# psoc4axx register map
Vendor: Cypress Semiconductor; Series: PSoC4Axx; File version: 1.0
CPU: CM0PLUS r0p1, little endian, no MPU, no FPU, VTOR, 2 interrupt priority bits
Registers are 32-bit, read-write, reset 0x0 unless marked. A register's access mark holds for its fields unless they carry their own. Offsets are from the block's base; [hi:lo] are bit positions; {n}, {i} and the like mark numbered series; 'fields as' and 'values as' point back to an identical list.

## CTB0 — Continuous Time Block
Base 0x40300000
Same registers: CTB1 0x40310000
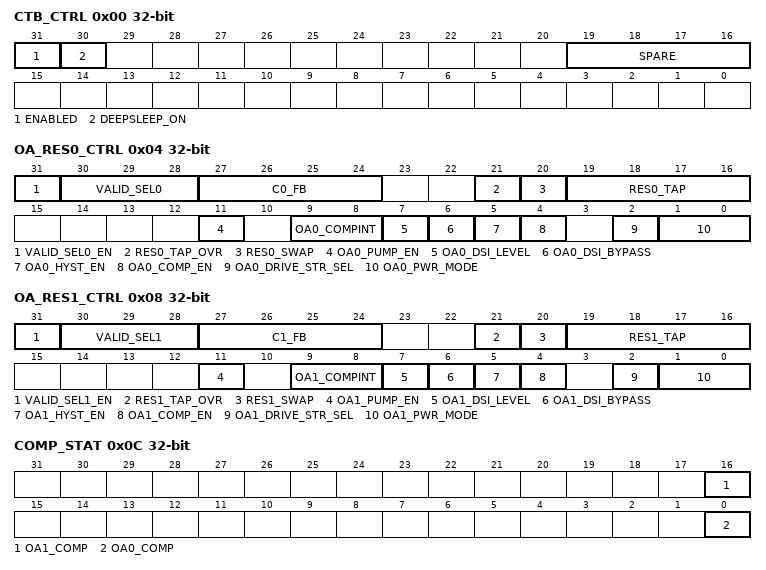
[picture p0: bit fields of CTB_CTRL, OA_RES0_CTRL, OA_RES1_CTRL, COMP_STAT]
0x00 CTB_CTRL — global CTB and power control
  [31] ENABLED — - 0: CTB IP disabled (put analog in power down, open all switches) - 1: CTB IP enabled
  [30] DEEPSLEEP_ON — - 0: CTB IP disabled off during DeepSleep power mode - 1: CTB IP remains enabled during DeepSleep power mode (if ENABLED=1)
  [19:16] SPARE — Spare controls, not yet designated, for late changes done with an ECO
0x04 OA_RES0_CTRL — Opamp0 and resistor0 control
  [31] VALID_SEL0_EN — Enable UAB Valid selection (UAB mode), otherwise ignore UAB Valid. Note that enabling UAB Valid selection also disables DeepSleep comparator operation.
  [30:28] VALID_SEL0 — Select which UAB Valid to use to sample the comparator output. This should match the UAB analog output connected to this comparator. The comparator output gets sampled at the negative edge of the selected UAB Valid signal. 0=UAB0 half 0 Valid output 1=UAB0 half 1 Valid output 2=UAB1 half 0 Valid output 3=UAB1 half 1 Valid output 4=UAB2 half 0 Valid output 5=UAB2 half 1 Valid output 6=UAB3 half 0 Valid output 7=UAB3 half 1 Valid output
  [27:24] C0_FB — Feed back Cap value
  [21] RES0_TAP_OVR — 1 - Override the control from hardware and close the switch connecting the resistor ladder tap point to the bottom of the ladder
  [20] RES0_SWAP — Swap Top and Bottom resistor value
  [19:16] RES0_TAP — PGA gain (resistor tap point): 0= gain 1.0 (disconnect resistor) 1= gain 1.42 2= gain 2.0 3= gain 2.78 4= gain 4.0 5= gain 5.82 6= gain 8.0 7= gain 10.67 8= gain 16.0 9= gain 21.33 10= gain 32.0
  [11] OA0_PUMP_EN — Opamp0 pump enable
  [9:8] OA0_COMPINT — Opamp0 comparator edge detect for interrupt and pulse mode of DSI (trigger)
    0=DISABLE (Disabled, no interrupts will be detected); 1=RISING (Rising edge); 2=FALLING (Falling edge); 3=BOTH (Both rising and falling edges)
  [7] OA0_DSI_LEVEL — Opamp0 comparator DSI (trigger) out level : 0=pulse, each time an edge is detected (see OA0_COMPINT) a pulse is sent out on DSI 1=level, DSI output is a synchronized version of the comparator output
  [6] OA0_DSI_BYPASS — Opamp0 bypass comparator output synchronization for DSI (trigger) output: 0=synchronize (level or pulse), 1=bypass (output async)
  [5] OA0_HYST_EN — Opamp0 hysteresis enable (10mV)
  [4] OA0_COMP_EN — Opamp0 comparator enable
  [2] OA0_DRIVE_STR_SEL — Opamp0 output strenght select 0=1x, 1=10x
  [1:0] OA0_PWR_MODE — Opamp0 power level
    0=OFF; 1=LOW (Low compensation setting (smallest cap, highest GBW). For gain=10: PM=60deg @ Cload=50pF for the output to pin driver and 10pF for the internal only driver); 2=MEDIUM (Medium compensation setting. For gain=4: PM=60deg @ Cload=50pF for the output to pin driver and 10pF for the internal only driver.); 3=HIGH (Highest compensation (largest cap, lowest GBW). For gain=1: PM=60deg @ Cload=50pF for the output to pin driver and 10pF for the internal only driver)
0x08 OA_RES1_CTRL — Opamp1 and resistor1 control
  [31] VALID_SEL1_EN — Enable UAB Valid selection (UAB mode), otherwise ignore UAB Valid. Note that enabling UAB Valid selection also disables DeepSleep comparator operation.
  [30:28] VALID_SEL1 — Select which UAB Valid to use to sample the comparator output. This should match the UAB analog output connected to this comparator. The comparator output gets sampled at the negative edge of the selected UAB Valid signal. 0=UAB0 half 0 Valid output 1=UAB0 half 1 Valid output 2=UAB1 half 0 Valid output 3=UAB1 half 1 Valid output 4=UAB2 half 0 Valid output 5=UAB2 half 1 Valid output 6=UAB3 half 0 Valid output 7=UAB3 half 1 Valid output
  [27:24] C1_FB — Feed back Cap value
  [21] RES1_TAP_OVR — 1 - Override the control from hardware and close the switch connecting the resistor ladder tap point to the bottom of the ladder
  [20] RES1_SWAP — Swap Top and Bottom resistor value
  [19:16] RES1_TAP — PGA gain (resistor tap point): see description of RES0_TAP
  [11] OA1_PUMP_EN — Opamp1 pump enable
  [9:8] OA1_COMPINT — Opamp1 comparator edge detect for interrupt and pulse mode of DSI (trigger)
    values as OA_RES0_CTRL.OA0_COMPINT
  [7] OA1_DSI_LEVEL — Opamp1 comparator DSI (trigger) out level : 0=pulse, each time an edge is detected (see OA1_COMPINT) a pulse is sent out on DSI 1=level, DSI output is a synchronized version of the comparator output
  [6] OA1_DSI_BYPASS — Opamp1 bypass comparator output synchronization for DSI (trigger) output: 0=synchronize (level or pulse), 1=bypass (output async)
  [5] OA1_HYST_EN — Opamp1 hysteresis enable (10mV)
  [4] OA1_COMP_EN — Opamp1 comparator enable
  [2] OA1_DRIVE_STR_SEL — Opamp1 output strenght select 0=1x, 1=10x
  [1:0] OA1_PWR_MODE — Opamp1 power level: see description of OA0_PWR_MODE
0x0C COMP_STAT ro — Comparator status
  [16] OA1_COMP — Opamp1 current comparator status
  [0] OA0_COMP — Opamp0 current comparator status
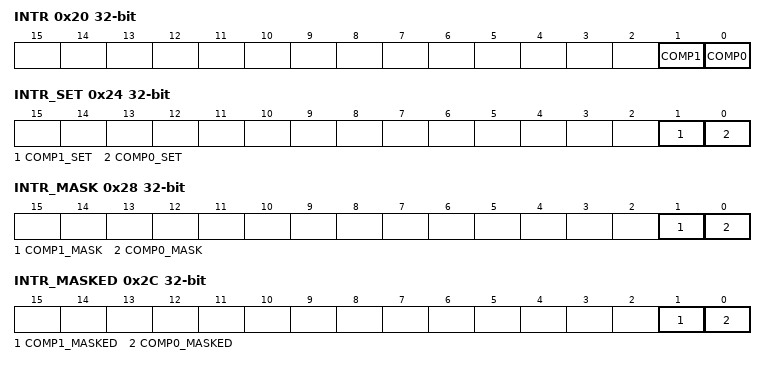
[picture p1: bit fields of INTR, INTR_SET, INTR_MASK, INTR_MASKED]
0x20 INTR — Interrupt request register
  [1] COMP1 — Comparator 1 Interrupt: hardware sets this interrupt when comparator 1 triggers. Write with '1' to clear bit.
  [0] COMP0 — Comparator 0 Interrupt: hardware sets this interrupt when comparator 0 triggers. Write with '1' to clear bit.
0x24 INTR_SET — Interrupt request set register
  [1] COMP1_SET — Write with '1' to set corresponding bit in interrupt request register.
  [0] COMP0_SET — Write with '1' to set corresponding bit in interrupt request register.
0x28 INTR_MASK — Interrupt request mask
  [1] COMP1_MASK — Mask bit for corresponding bit in interrupt request register.
  [0] COMP0_MASK — Mask bit for corresponding bit in interrupt request register.
0x2C INTR_MASKED ro — Interrupt request masked
  [1] COMP1_MASKED — Logical and of corresponding request and mask bits.
  [0] COMP0_MASKED — Logical and of corresponding request and mask bits.
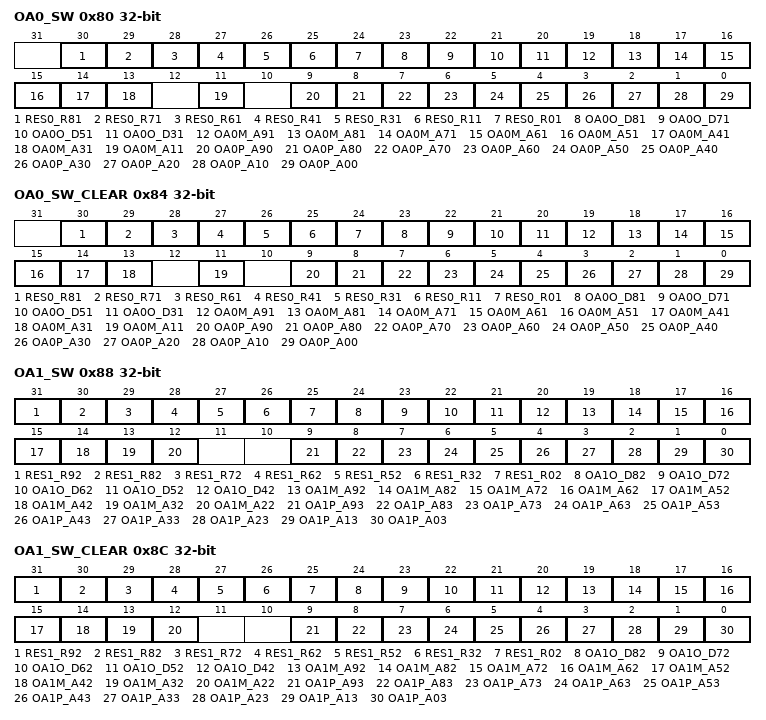
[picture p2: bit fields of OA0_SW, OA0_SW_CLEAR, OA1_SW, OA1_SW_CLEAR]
0x80 OA0_SW — Opamp0 switch control
  [30] RES0_R81 — Resistor0 tap to Opamp0 positive terminal
  [29] RES0_R71 — Resistor0 tap to Opamp0 negative terminal
  [28] RES0_R61 — Resistor0 bottom to VSSA
  [27] RES0_R41 — Resistor0 bottom to Opamp1 negative terminal
  [26] RES0_R31 — Resistor0 bottom to Opamp0 negative terminal
  [25] RES0_R11 — Resistor0 bottom to Opamp1 output
  [24] RES0_R01 — Resistor0 bottom to Pin P1
  [23] OA0O_D81 — Opamp0 output switch to short 1x with 10x drive
  [22] OA0O_D71 — Opamp0 output to vref0
  [21] OA0O_D51 — Opamp0 output to ctbbus2
  [20] OA0O_D31 — Opamp0 output to ctbbus0
  [19] OA0M_A91 — Opamp0 negative terminal to pin P2
  [18] OA0M_A81 — Opamp0 negative terminal to Opamp0 output
  [17] OA0M_A71 — Opamp0 negative terminal to vref0
  [16] OA0M_A61 — Opamp0 negative terminal to ctbbus3
  [15] OA0M_A51 — Opamp0 negative terminal to ctbbus2
  [14] OA0M_A41 — Opamp0 negative terminal to ctbbus1
  [13] OA0M_A31 — Opamp0 negative terminal to ctbbus0
  [11] OA0M_A11 — Opamp0 negative terminal to pin P1
  [9] OA0P_A90 — Opamp0 positive terminal to uabin1
  [8] OA0P_A80 — Opamp0 positive terminal to uabin0
  [7] OA0P_A70 — Opamp0 positive terminal to vref0
  [6] OA0P_A60 — Opamp0 positive terminal to ctbbus3
  [5] OA0P_A50 — Opamp0 positive terminal to ctbbus2
  [4] OA0P_A40 — Opamp0 positive terminal to ctbbus1
  [3] OA0P_A30 — Opamp0 positive terminal to ctbbus0
  [2] OA0P_A20 — Opamp0 positive terminal to pin P0
  [1] OA0P_A10 — Opamp0 positive terminal to pin P1
  [0] OA0P_A00 — Opamp0 positive terminal to amuxbusa
0x84 OA0_SW_CLEAR — Opamp0 switch control clear
  [30] RES0_R81 — see corresponding bit in OA0_SW
  [29] RES0_R71 — see corresponding bit in OA0_SW
  [28] RES0_R61 — see corresponding bit in OA0_SW
  [27] RES0_R41 — see corresponding bit in OA0_SW
  [26] RES0_R31 — see corresponding bit in OA0_SW
  [25] RES0_R11 — see corresponding bit in OA0_SW
  [24] RES0_R01 — see corresponding bit in OA0_SW
  [23] OA0O_D81 — see corresponding bit in OA0_SW
  [22] OA0O_D71 — see corresponding bit in OA0_SW
  [21] OA0O_D51 — see corresponding bit in OA0_SW
  [20] OA0O_D31 — see corresponding bit in OA0_SW
  [19] OA0M_A91 — see corresponding bit in OA0_SW
  [18] OA0M_A81 — see corresponding bit in OA0_SW
  [17] OA0M_A71 — see corresponding bit in OA0_SW
  [16] OA0M_A61 — see corresponding bit in OA0_SW
  [15] OA0M_A51 — see corresponding bit in OA0_SW
  [14] OA0M_A41 — see corresponding bit in OA0_SW
  [13] OA0M_A31 — see corresponding bit in OA0_SW
  [11] OA0M_A11 — see corresponding bit in OA0_SW
  [9] OA0P_A90 — see corresponding bit in OA0_SW
  [8] OA0P_A80 — see corresponding bit in OA0_SW
  [7] OA0P_A70 — see corresponding bit in OA0_SW
  [6] OA0P_A60 — see corresponding bit in OA0_SW
  [5] OA0P_A50 — see corresponding bit in OA0_SW
  [4] OA0P_A40 — see corresponding bit in OA0_SW
  [3] OA0P_A30 — see corresponding bit in OA0_SW
  [2] OA0P_A20 — see corresponding bit in OA0_SW
  [1] OA0P_A10 — see corresponding bit in OA0_SW
  [0] OA0P_A00 — see corresponding bit in OA0_SW
0x88 OA1_SW — Opamp1 switch control
  [31] RES1_R92 — Resistor1 tap to Opamp0 positive terminal
  [30] RES1_R82 — Resistor1 tap to Opamp1 positive terminal
  [29] RES1_R72 — Resistor1 tap to Opamp1 negative terminal
  [28] RES1_R62 — Resistor1 bottom to VSSA
  [27] RES1_R52 — Resistor1 bottom to Resistor0 bottom
  [26] RES1_R32 — Resistor1 bottom to Opamp1 negative terminal
  [25] RES1_R02 — Resistor1 bottom to pin P4
  [24] OA1O_D82 — Opamp1 output switch to short 1x with 10x drive
  [23] OA1O_D72 — Opamp1 output to vref1
  [22] OA1O_D62 — Opamp1 output to ctbbus3
  [21] OA1O_D52 — Opamp1 output to ctbbus2
  [20] OA1O_D42 — Opamp1 output to ctbbus1
  [19] OA1M_A92 — Opamp1 negative terminal to pin P3
  [18] OA1M_A82 — Opamp1 negative terminal to Opamp1 output
  [17] OA1M_A72 — Opamp1 negative terminal to vref1
  [16] OA1M_A62 — Opamp1 negative terminal to ctbbus3
  [15] OA1M_A52 — Opamp1 negative terminal to ctbbus2
  [14] OA1M_A42 — Opamp1 negative terminal to ctbbus1
  [13] OA1M_A32 — Opamp1 negative terminal to ctbbus0
  [12] OA1M_A22 — Opamp1 negative terminal to pin P4
  [9] OA1P_A93 — Opamp1 positive terminal to uabin1
  [8] OA1P_A83 — Opamp1 positive terminal to uabin0
  [7] OA1P_A73 — Opamp1 positive terminal to vref1
  [6] OA1P_A63 — Opamp1 positive terminal to ctbbus3
  [5] OA1P_A53 — Opamp1 positive terminal to ctbbus2
  [4] OA1P_A43 — Opamp1 positive terminal to ctbbus1
  [3] OA1P_A33 — Opamp1 positive terminal to ctbbus0
  [2] OA1P_A23 — Opamp1 positive terminal to pin P4
  [1] OA1P_A13 — Opamp1 positive terminal to pin P5
  [0] OA1P_A03 — Opamp1 positive terminal to amuxbusb
0x8C OA1_SW_CLEAR — Opamp1 switch control clear
  [31] RES1_R92 — see corresponding bit in OA1_SW
  [30] RES1_R82 — see corresponding bit in OA1_SW
  [29] RES1_R72 — see corresponding bit in OA1_SW
  [28] RES1_R62 — see corresponding bit in OA1_SW
  [27] RES1_R52 — see corresponding bit in OA1_SW
  [26] RES1_R32 — see corresponding bit in OA1_SW
  [25] RES1_R02 — see corresponding bit in OA1_SW
  [24] OA1O_D82 — see corresponding bit in OA1_SW
  [23] OA1O_D72 — see corresponding bit in OA1_SW
  [22] OA1O_D62 — see corresponding bit in OA1_SW
  [21] OA1O_D52 — see corresponding bit in OA1_SW
  [20] OA1O_D42 — see corresponding bit in OA1_SW
  [19] OA1M_A92 — see corresponding bit in OA1_SW
  [18] OA1M_A82 — see corresponding bit in OA1_SW
  [17] OA1M_A72 — see corresponding bit in OA1_SW
  [16] OA1M_A62 — see corresponding bit in OA1_SW
  [15] OA1M_A52 — see corresponding bit in OA1_SW
  [14] OA1M_A42 — see corresponding bit in OA1_SW
  [13] OA1M_A32 — see corresponding bit in OA1_SW
  [12] OA1M_A22 — see corresponding bit in OA1_SW
  [9] OA1P_A93 — see corresponding bit in OA1_SW
  [8] OA1P_A83 — see corresponding bit in OA1_SW
  [7] OA1P_A73 — see corresponding bit in OA1_SW
  [6] OA1P_A63 — see corresponding bit in OA1_SW
  [5] OA1P_A53 — see corresponding bit in OA1_SW
  [4] OA1P_A43 — see corresponding bit in OA1_SW
  [3] OA1P_A33 — see corresponding bit in OA1_SW
  [2] OA1P_A23 — see corresponding bit in OA1_SW
  [1] OA1P_A13 — see corresponding bit in OA1_SW
  [0] OA1P_A03 — see corresponding bit in OA1_SW
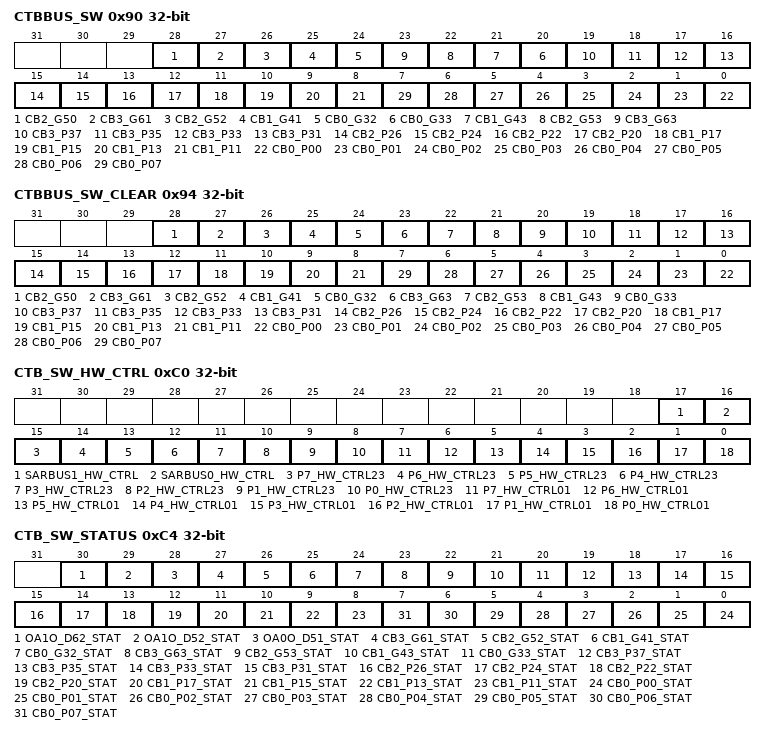
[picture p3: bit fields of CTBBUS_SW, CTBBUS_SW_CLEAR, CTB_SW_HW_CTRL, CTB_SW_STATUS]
0x90 CTBBUS_SW — CTB bus switch control
  [28] CB2_G50 — ctbbus2 ctbbus3
  [27] CB3_G61 — ctbbus3 sarbus1
  [26] CB2_G52 — ctbbus2 sarbus0
  [25] CB1_G41 — ctbbus1 sarbus1
  [24] CB0_G32 — ctbbus0 sarbus0
  [n+20] CB{n}_G{10n+33} (n=0..3) — ctbbus{n} right neighbor
  [19] CB3_P37 — P7 ctbbus3
  [18] CB3_P35 — P5 ctbbus3
  [17] CB3_P33 — P3 ctbbus3
  [16] CB3_P31 — P1 ctbbus3
  [15] CB2_P26 — P6 ctbbus2
  [14] CB2_P24 — P4 ctbbus2
  [13] CB2_P22 — P2 ctbbus2
  [12] CB2_P20 — P0 ctbbus2
  [11] CB1_P17 — P7 ctbbus1
  [10] CB1_P15 — P5 ctbbus1
  [9] CB1_P13 — P3 ctbbus1
  [8] CB1_P11 — P1 ctbbus1
  [n] CB0_P{n:02} (n=0..7) — P{n} ctbbus0
0x94 CTBBUS_SW_CLEAR — CTB bus switch control clear
  [28] CB2_G50 — see corresponding bit in CTBBUS_SW
  [27] CB3_G61 — see corresponding bit in CTBBUS_SW
  [26] CB2_G52 — see corresponding bit in CTBBUS_SW
  [25] CB1_G41 — see corresponding bit in CTBBUS_SW
  [24] CB0_G32 — see corresponding bit in CTBBUS_SW
  [23] CB3_G63 — see corresponding bit in CTBBUS_SW
  [22] CB2_G53 — see corresponding bit in CTBBUS_SW
  [21] CB1_G43 — see corresponding bit in CTBBUS_SW
  [20] CB0_G33 — see corresponding bit in CTBBUS_SW
  [19] CB3_P37 — see corresponding bit in CTBBUS_SW
  [18] CB3_P35 — see corresponding bit in CTBBUS_SW
  [17] CB3_P33 — see corresponding bit in CTBBUS_SW
  [16] CB3_P31 — see corresponding bit in CTBBUS_SW
  [15] CB2_P26 — see corresponding bit in CTBBUS_SW
  [14] CB2_P24 — see corresponding bit in CTBBUS_SW
  [13] CB2_P22 — see corresponding bit in CTBBUS_SW
  [12] CB2_P20 — see corresponding bit in CTBBUS_SW
  [11] CB1_P17 — see corresponding bit in CTBBUS_SW
  [10] CB1_P15 — see corresponding bit in CTBBUS_SW
  [9] CB1_P13 — see corresponding bit in CTBBUS_SW
  [8] CB1_P11 — see corresponding bit in CTBBUS_SW
  [n] CB0_P{n:02} (n=0..7) — see corresponding bit in CTBBUS_SW
0xC0 CTB_SW_HW_CTRL — CTB bus switch control status
  [17] SARBUS1_HW_CTRL — sarbus1 switches (G41, G61) (dsi_oe[1])
  [16] SARBUS0_HW_CTRL — sarbus0 switches (G32, G52) (dsi_oe[0])
  [15] P7_HW_CTRL23 — for P37 (dsi_out[7])
  [14] P6_HW_CTRL23 — for P26 (dsi_out[6])
  [13] P5_HW_CTRL23 — for P35 (dsi_out[5])
  [12] P4_HW_CTRL23 — for P24 (dsi_out[4])
  [11] P3_HW_CTRL23 — for P33, D52, D62 (dsi_out[3])
  [10] P2_HW_CTRL23 — for P22, D51 (dsi_out[2])
  [9] P1_HW_CTRL23 — for P31 (dsi_out[1])
  [8] P0_HW_CTRL23 — for P20 (dsi_out[0])
  [7] P7_HW_CTRL01 — for P07, P17 (dsi_out[7])
  [6] P6_HW_CTRL01 — for P06 (dsi_out[6])
  [5] P5_HW_CTRL01 — for P05, P15 (dsi_out[5])
  [4] P4_HW_CTRL01 — for P04 (dsi_out[4])
  [3] P3_HW_CTRL01 — for P03, P13 (dsi_out[3])
  [2] P2_HW_CTRL01 — for P02 (dsi_out[2])
  [1] P1_HW_CTRL01 — for P01, P11 (dsi_out[1])
  [0] P0_HW_CTRL01 — for P00 (dsi_out[0])
0xC4 CTB_SW_STATUS ro — CTB bus switch control status
  [30] OA1O_D62_STAT — see OA1O_D62 bit in OA1_SW
  [29] OA1O_D52_STAT — see OA1O_D52 bit in OA1_SW
  [28] OA0O_D51_STAT — see OA0O_D51 bit in OA0_SW
  [27] CB3_G61_STAT — see corresponding bit in CTBBUS_SW
  [26] CB2_G52_STAT — see corresponding bit in CTBBUS_SW
  [25] CB1_G41_STAT — see corresponding bit in CTBBUS_SW
  [24] CB0_G32_STAT — see corresponding bit in CTBBUS_SW
  [23] CB3_G63_STAT — see corresponding bit in CTBBUS_SW
  [22] CB2_G53_STAT — see corresponding bit in CTBBUS_SW
  [21] CB1_G43_STAT — see corresponding bit in CTBBUS_SW
  [20] CB0_G33_STAT — see corresponding bit in CTBBUS_SW
  [19] CB3_P37_STAT — see corresponding bit in CTBBUS_SW
  [18] CB3_P35_STAT — see corresponding bit in CTBBUS_SW
  [17] CB3_P33_STAT — see corresponding bit in CTBBUS_SW
  [16] CB3_P31_STAT — see corresponding bit in CTBBUS_SW
  [15] CB2_P26_STAT — see corresponding bit in CTBBUS_SW
  [14] CB2_P24_STAT — see corresponding bit in CTBBUS_SW
  [13] CB2_P22_STAT — see corresponding bit in CTBBUS_SW
  [12] CB2_P20_STAT — see corresponding bit in CTBBUS_SW
  [11] CB1_P17_STAT — see corresponding bit in CTBBUS_SW
  [10] CB1_P15_STAT — see corresponding bit in CTBBUS_SW
  [9] CB1_P13_STAT — see corresponding bit in CTBBUS_SW
  [8] CB1_P11_STAT — see corresponding bit in CTBBUS_SW
  [n] CB0_P{n:02}_STAT (n=0..7) — see corresponding bit in CTBBUS_SW
0xF00 OA0_OFFSET_TRIM — Opamp0 trim control
  [5:0] OA0_OFFSET_TRIM — Opamp0 offset trim
0xF04 OA0_SLOPE_OFFSET_TRIM — Opamp0 trim control
  [5:0] OA0_SLOPE_OFFSET_TRIM — Opamp0 slope offset drift trim
0xF08 OA0_COMP_TRIM — Opamp0 trim control
  [1:0] OA0_COMP_TRIM — Opamp 0 Compensation Capacitor Trim
0xF0C OA1_OFFSET_TRIM — Opamp1 trim control
  [5:0] OA1_OFFSET_TRIM — Opamp1 offset trim
0xF10 OA1_SLOPE_OFFSET_TRIM — Opamp1 trim control
  [5:0] OA1_SLOPE_OFFSET_TRIM — Opamp1 slope offset drift trim
0xF14 OA1_COMP_TRIM — Opamp1 trim control
  [1:0] OA1_COMP_TRIM — Opamp 1 Compensation Capacitor Trim
0xF18 RMP_TRIM — Risk Mitigation bits
  [3:0] RMP_TRIM — Risk Mitigation Trim bits
